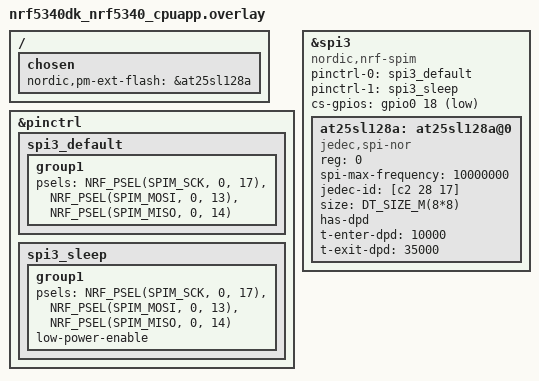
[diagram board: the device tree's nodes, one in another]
/*
 * Copyright (c) 2023 Victor Chavez
 *
 * SPDX-License-Identifier: GPL-3.0-or-later
 */

 &pinctrl {
	spi3_default: spi3_default {
		group1 {
			psels = <NRF_PSEL(SPIM_SCK, 0, 17)>,
				<NRF_PSEL(SPIM_MOSI, 0, 13)>,
				<NRF_PSEL(SPIM_MISO, 0, 14)>;
			};
	};

	spi3_sleep: spi3_sleep {
		group1 {
			psels = <NRF_PSEL(SPIM_SCK, 0, 17)>,
				<NRF_PSEL(SPIM_MOSI, 0, 13)>,
				<NRF_PSEL(SPIM_MISO, 0, 14)>;
			low-power-enable;
		};
	};
};

/ {
    chosen {
        nordic,pm-ext-flash = &at25sl128a;
    };
};

&spi3  {
    status = "okay";
    compatible = "nordic,nrf-spim";
    pinctrl-0 = <&spi3_default>;
    pinctrl-1 = <&spi3_sleep>;
    pinctrl-names = "default", "sleep";
    // Use Integrated flash MX25R6435F from DK 
    cs-gpios = <&gpio0 18 GPIO_ACTIVE_LOW>;
    at25sl128a: at25sl128a@0 {
		compatible = "jedec,spi-nor";
		reg = <0>;
		status = "okay";
		spi-max-frequency = <10000000>;
		jedec-id = [c2 28 17];
		size = <DT_SIZE_M(8*8)>;
		has-dpd;
		t-enter-dpd = <10000>;
		t-exit-dpd = <35000>;
	};
};
